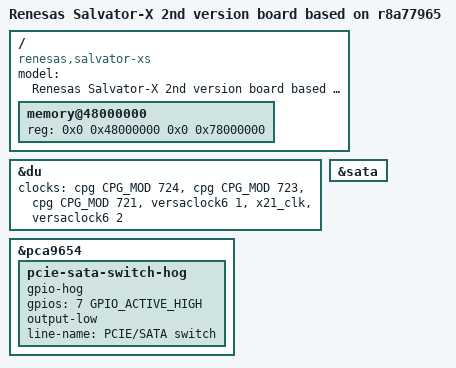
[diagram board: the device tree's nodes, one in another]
// SPDX-License-Identifier: GPL-2.0
/*
 * Device Tree Source for the Salvator-X 2nd version board with R-Car M3-N
 *
 * Copyright (C) 2017 Renesas Electronics Corp.
 */

/dts-v1/;
#include "r8a77965.dtsi"
#include "salvator-xs.dtsi"

/ {
	model = "Renesas Salvator-X 2nd version board based on r8a77965";
	compatible = "renesas,salvator-xs", "renesas,r8a77965";

	memory@48000000 {
		device_type = "memory";
		/* first 128MB is reserved for secure area. */
		reg = <0x0 0x48000000 0x0 0x78000000>;
	};
};

&du {
	clocks = <&cpg CPG_MOD 724>,
		 <&cpg CPG_MOD 723>,
		 <&cpg CPG_MOD 721>,
		 <&versaclock6 1>,
		 <&x21_clk>,
		 <&versaclock6 2>;
	clock-names = "du.0", "du.1", "du.3",
		      "dclkin.0", "dclkin.1", "dclkin.3";
};

&pca9654 {
	pcie-sata-switch-hog {
		gpio-hog;
		gpios = <7 GPIO_ACTIVE_HIGH>;
		output-low; /* enable SATA by default */
		line-name = "PCIE/SATA switch";
	};
};

/* SW12-7 must be set 'Off' (MD12 set to 1) which is not the default! */
&sata {
	status = "okay";
};
